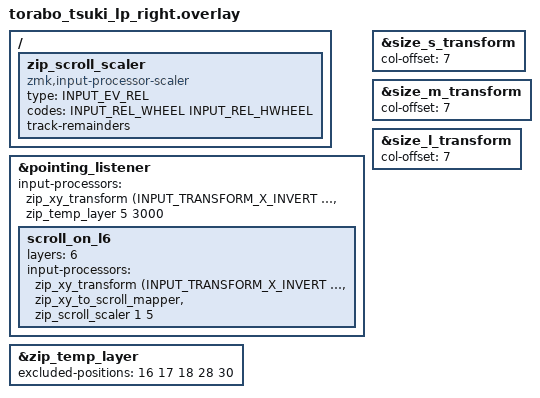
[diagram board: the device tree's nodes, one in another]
#include "torabo_tsuki_lp.dtsi"
#include <input/processors.dtsi>
#include <dt-bindings/zmk/input_transform.h>
#include <zephyr/dt-bindings/input/input-event-codes.h>

/ {
    zip_scroll_scaler: zip_scroll_scaler {
        compatible = "zmk,input-processor-scaler";
        #input-processor-cells = <2>;
        type = <INPUT_EV_REL>;
        codes = <INPUT_REL_WHEEL INPUT_REL_HWHEEL>;
        track-remainders;
    };
};

&pointing_listener {
    input-processors = <&zip_xy_transform (INPUT_TRANSFORM_X_INVERT | INPUT_TRANSFORM_Y_INVERT) &zip_temp_layer 5 3000>;
    scroll_on_l6 {
        layers = <6>;
        input-processors = <
            &zip_xy_transform (INPUT_TRANSFORM_X_INVERT | INPUT_TRANSFORM_Y_INVERT)
            &zip_xy_to_scroll_mapper
            &zip_scroll_scaler 1 5
        >;
    };
};
&zip_temp_layer {
    excluded-positions = <16 17 18 28 30>;
};
&size_s_transform {
    col-offset = <7>;
};
&size_m_transform {
    col-offset = <7>;
};
&size_l_transform {
    col-offset = <7>;
};
